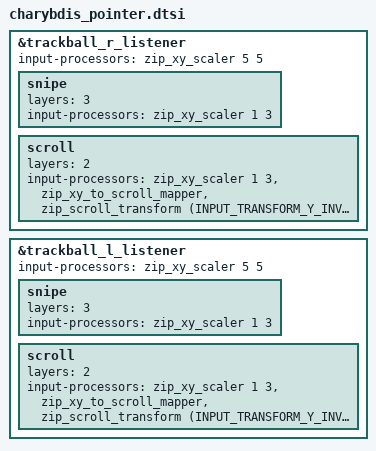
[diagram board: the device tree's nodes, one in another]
#include <input/processors.dtsi>
#include <dt-bindings/zmk/input_transform.h>

&trackball_r_listener {
    /* base processor chain on all layers */
    input-processors = <&zip_xy_scaler 5 5>;

    snipe {
        layers = <3>;
        input-processors = <&zip_xy_scaler 1 3>;
    };

    scroll {
        layers = <2>;
        input-processors = <
            &zip_xy_scaler 1 3
            &zip_xy_to_scroll_mapper
            &zip_scroll_transform (INPUT_TRANSFORM_Y_INVERT)
        >;
    };
};

&trackball_l_listener {
    /* base processor chain on all layers */
    input-processors = <&zip_xy_scaler 5 5>;

    snipe {
        layers = <3>;
        input-processors = <&zip_xy_scaler 1 3>;
    };

    scroll {
        layers = <2>;
        input-processors = <
            &zip_xy_scaler 1 3
            &zip_xy_to_scroll_mapper
            &zip_scroll_transform (INPUT_TRANSFORM_Y_INVERT)
        >;
    };
};
